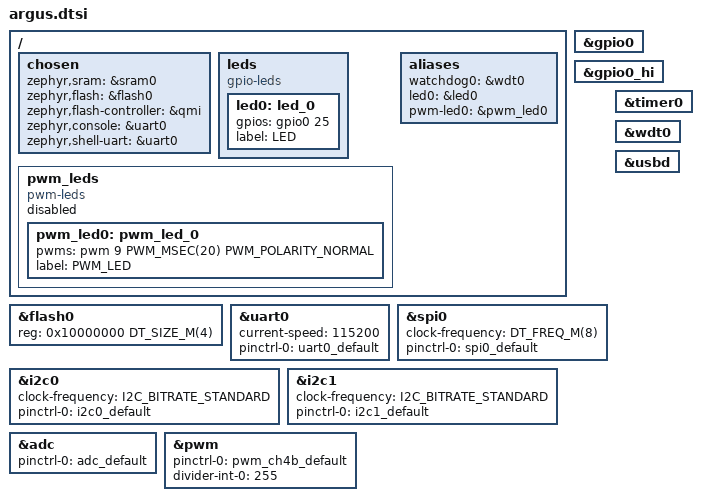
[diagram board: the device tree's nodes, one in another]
/*
 * Based on Zephyr's rpi_pico2 board
 * Copyright (c) 2024 Andrew Featherstone
 * Copyright (c) 2021 Yonatan Schachter
 *
 * SPDX-License-Identifier: Apache-2.0
 */

/* PLACEHOLDER: every pin, the flash size and the console below are still the
 * Raspberry Pi Pico 2's. Replace them with the ARGUS pin map from the hardware
 * team before flashing this onto ARGUS hardware.
 */

#include <freq.h>

#include <zephyr/dt-bindings/i2c/i2c.h>
#include <zephyr/dt-bindings/pwm/pwm.h>

#include "argus-pinctrl.dtsi"

/ {
	chosen {
		zephyr,sram = &sram0;
		zephyr,flash = &flash0;
		zephyr,flash-controller = &qmi;
		zephyr,console = &uart0;
		zephyr,shell-uart = &uart0;
	};

	leds {
		compatible = "gpio-leds";

		led0: led_0 {
			gpios = <&gpio0 25 GPIO_ACTIVE_HIGH>;
			label = "LED";
		};
	};

	pwm_leds {
		compatible = "pwm-leds";
		status = "disabled";

		pwm_led0: pwm_led_0 {
			pwms = <&pwm 9 PWM_MSEC(20) PWM_POLARITY_NORMAL>;
			label = "PWM_LED";
		};
	};

	aliases {
		watchdog0 = &wdt0;
		led0 = &led0;
		pwm-led0 = &pwm_led0;
	};
};

&flash0 {
	reg = <0x10000000 DT_SIZE_M(4)>;
};

&uart0 {
	current-speed = <115200>;
	status = "okay";
	pinctrl-0 = <&uart0_default>;
	pinctrl-names = "default";
};

gpio0_lo: &gpio0 {
	status = "okay";
};

/* GPIO 32-47, only present on the RP2350B */
&gpio0_hi {
	status = "okay";
};

&spi0 {
	clock-frequency = <DT_FREQ_M(8)>;
	pinctrl-0 = <&spi0_default>;
	pinctrl-names = "default";
};

&i2c0 {
	clock-frequency = <I2C_BITRATE_STANDARD>;
	pinctrl-0 = <&i2c0_default>;
	pinctrl-names = "default";
	status = "okay";
};

&i2c1 {
	clock-frequency = <I2C_BITRATE_STANDARD>;
	pinctrl-0 = <&i2c1_default>;
	pinctrl-names = "default";
	status = "okay";
};

&adc {
	pinctrl-0 = <&adc_default>;
	pinctrl-names = "default";
	status = "okay";
};

&pwm {
	pinctrl-0 = <&pwm_ch4b_default>;
	pinctrl-names = "default";
	divider-int-0 = <255>;
};

&timer0 {
	status = "okay";
};

&wdt0 {
	status = "okay";
};

zephyr_udc0: &usbd {
	status = "okay";
};
